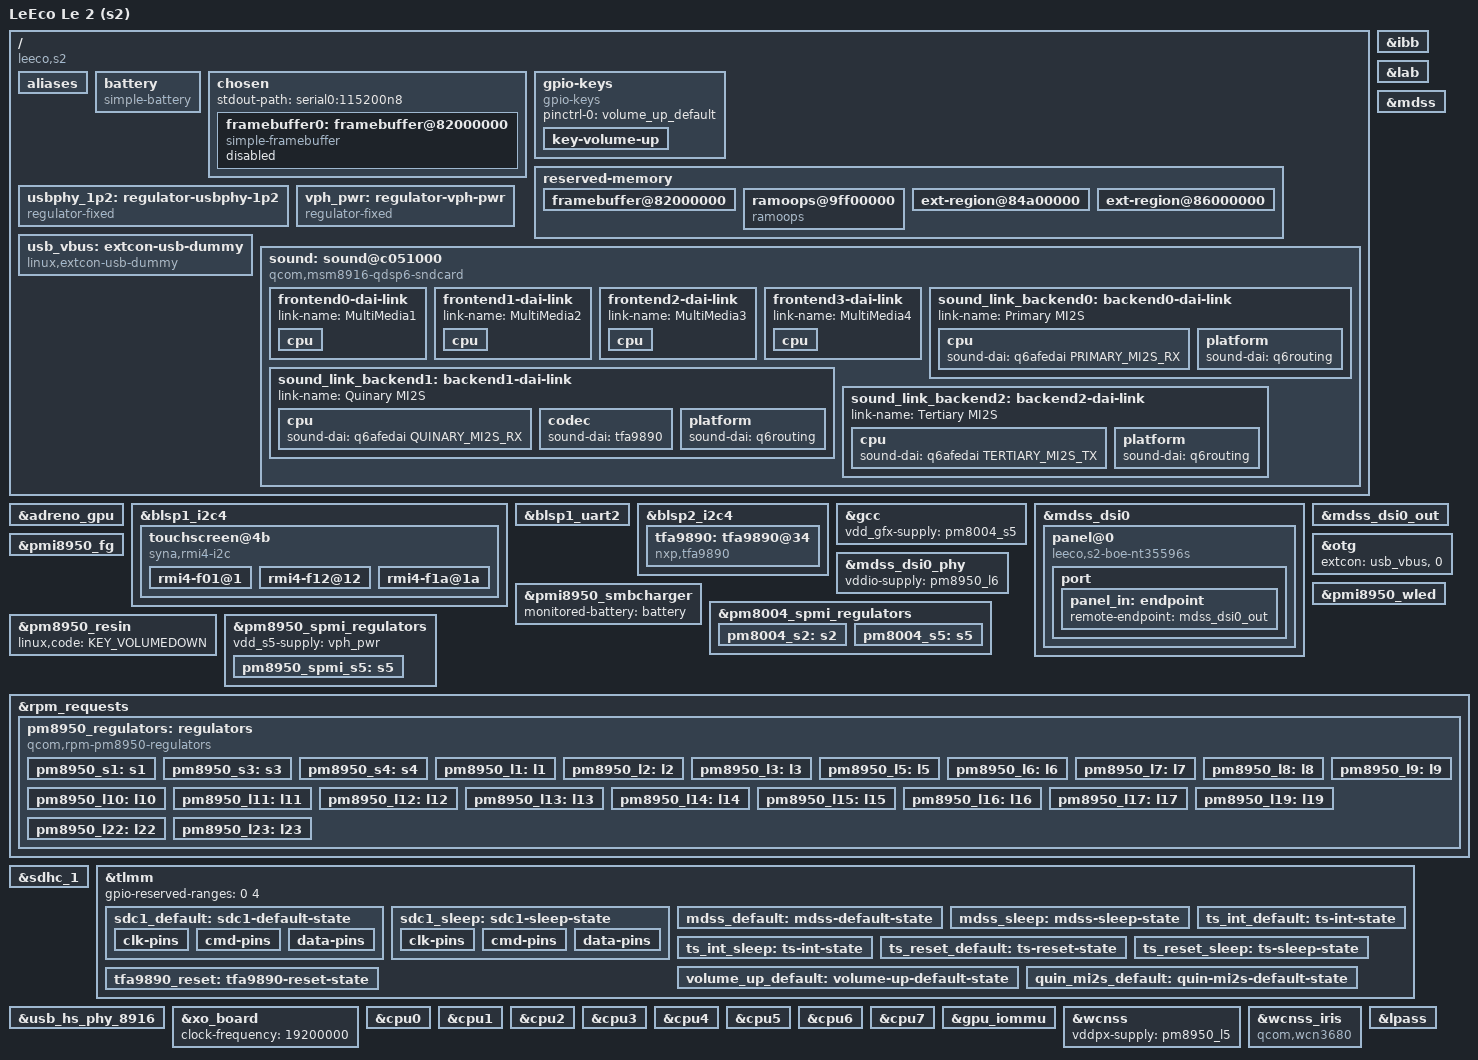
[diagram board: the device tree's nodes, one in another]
// SPDX-License-Identifier: BSD-3-Clause
/*
 * LeEco Le 2 (s2)
 */

/dts-v1/;

#include <dt-bindings/gpio/gpio.h>
#include <dt-bindings/input/input.h>
#include <dt-bindings/interrupt-controller/irq.h>

#include "msm8976.dtsi"
#include "pm8004.dtsi"
#include "pm8950.dtsi"
#include "pmi8950.dtsi"

/ {
	model = "LeEco Le 2 (s2)";
	compatible = "leeco,s2", "qcom,msm8976";
	chassis-type = "handset";

	aliases {
		mmc0 = &sdhc_1;
		serial0 = &blsp1_uart2;
	};

	battery: battery {
		compatible = "simple-battery";

		charge-full-design-microamp-hours = <3000000>;
		constant-charge-current-max-microamp = <1500000>;
		voltage-min-design-microvolt = <3400000>;
		voltage-max-design-microvolt = <4400000>;
	};

	chosen {
		stdout-path = "serial0:115200n8";

		#address-cells = <2>;
		#size-cells = <2>;
		ranges;

		framebuffer0: framebuffer@82000000 {
			compatible = "simple-framebuffer";
			reg = <0x0 0x82000000 0x0 (4352 * 1920)>;
			width = <1080>;
			height = <1920>;
			stride = <4352>;
			format = "a8r8g8b8";

			power-domains = <&gcc MDSS_GDSC>;

			clocks = <&gcc GCC_MDSS_AHB_CLK>,
				 <&gcc GCC_MDSS_AXI_CLK>,
				 <&gcc GCC_MDSS_VSYNC_CLK>,
				 <&gcc GCC_MDSS_MDP_CLK>,
				 <&gcc GCC_MDSS_BYTE0_CLK>,
				 <&gcc GCC_MDSS_PCLK0_CLK>,
				 <&gcc GCC_MDSS_ESC0_CLK>;

			status = "disabled";
		};
	};

	gpio-keys {
		compatible = "gpio-keys";

		pinctrl-0 = <&volume_up_default>;
		pinctrl-names = "default";

		key-volume-up {
			label = "Volume Up";
			gpios = <&tlmm 113 GPIO_ACTIVE_LOW>;
			linux,code = <KEY_VOLUMEUP>;
		};
	};

	reserved-memory {
		framebuffer@82000000 {
			reg = <0x0 0x82000000 0x0 0x2800000>;
			no-map;
		};

		ramoops@9ff00000 {
			compatible = "ramoops";
			reg = <0x0 0x9ff00000 0x0 0x100000>;
			record-size = <0x10000>;
			console-size = <0x60000>;
			pmsg-size = <0x20000>;
			no-map;
		};

		ext-region@84a00000 {
			reg = <0x0 0x84a00000 0x0 0x1100000>;
			no-map;
		};

		ext-region@86000000 {
			reg = <0x0 0x86000000 0x0 0x300000>;
			no-map;
		};
	};

	usbphy_1p2: regulator-usbphy-1p2 {
		compatible = "regulator-fixed";
		regulator-name = "usbphy-1p2";
		regulator-always-on;
		regulator-boot-on;
		regulator-min-microvolt = <1200000>;
		regulator-max-microvolt = <1200000>;
		vin-supply = <&vph_pwr>;
	};

	usb_vbus: extcon-usb-dummy {
		compatible = "linux,extcon-usb-dummy";
	};

	vph_pwr: regulator-vph-pwr {
		compatible = "regulator-fixed";
		regulator-name = "vph-pwr";
		regulator-always-on;
		regulator-boot-on;
	};

	sound: sound@c051000 {
		compatible = "qcom,msm8916-qdsp6-sndcard";
		model = "msm8976-leeco-s2";
		reg = <0x0 0x0c051000 0x0 0x4>, <0x0 0x0c051004 0x0 0x4>,
		      <0x0 0x0c052000 0x0 0x4>;
		reg-names = "mic-iomux", "spkr-iomux", "quin-iomux";

		pinctrl-0 = <&quin_mi2s_default>;
		pinctrl-names = "default";

		widgets = "Speaker", "Internal Speaker";
		audio-routing = "Internal Speaker", "OUT";

		status = "okay";

		frontend0-dai-link {
			link-name = "MultiMedia1";

			cpu {
				sound-dai = <&q6asmdai MSM_FRONTEND_DAI_MULTIMEDIA1>;
			};
		};

		frontend1-dai-link {
			link-name = "MultiMedia2";

			cpu {
				sound-dai = <&q6asmdai MSM_FRONTEND_DAI_MULTIMEDIA2>;
			};
		};

		frontend2-dai-link {
			link-name = "MultiMedia3";

			cpu {
				sound-dai = <&q6asmdai MSM_FRONTEND_DAI_MULTIMEDIA3>;
			};
		};

		frontend3-dai-link {
			link-name = "MultiMedia4";

			cpu {
				sound-dai = <&q6asmdai MSM_FRONTEND_DAI_MULTIMEDIA4>;
			};
		};

		sound_link_backend0: backend0-dai-link {
			link-name = "Primary MI2S";

			cpu {
				sound-dai = <&q6afedai PRIMARY_MI2S_RX>;
			};
			platform {
				sound-dai = <&q6routing>;
			};
		};

		sound_link_backend1: backend1-dai-link {
			link-name = "Quinary MI2S";

			cpu {
				sound-dai = <&q6afedai QUINARY_MI2S_RX>;
			};
			codec {
				sound-dai = <&tfa9890>;
			};
			platform {
				sound-dai = <&q6routing>;
			};
		};

		sound_link_backend2: backend2-dai-link {
			link-name = "Tertiary MI2S";

			cpu {
				sound-dai = <&q6afedai TERTIARY_MI2S_TX>;
			};
			platform {
				sound-dai = <&q6routing>;
			};
		};
	};
};

&adreno_gpu {
	status = "okay";
};

&blsp1_i2c4 {
	status = "okay";

	touchscreen@4b {
		compatible = "syna,rmi4-i2c";
		reg = <0x4b>;

		interrupts-extended = <&tlmm 65 IRQ_TYPE_EDGE_FALLING>;

		pinctrl-0 = <&ts_int_default>, <&ts_reset_default>;
		pinctrl-1 = <&ts_int_sleep>, <&ts_reset_sleep>;
		pinctrl-names = "default", "sleep";

		vdd-supply = <&pm8950_l17>;
		vio-supply = <&pm8950_l6>;

		reset-gpios = <&tlmm 64 GPIO_ACTIVE_LOW>;

		syna,reset-delay-ms = <200>;
		syna,startup-delay-ms = <200>;

		#address-cells = <1>;
		#size-cells = <0>;

		rmi4-f01@1 {
			reg = <0x1>;
			syna,nosleep-mode = <1>;
		};

		rmi4-f12@12 {
			reg = <0x12>;
			syna,sensor-type = <1>;
		};

		rmi4-f1a@1a {
			reg = <0x1a>;
			linux,keycodes = <KEY_MENU KEY_HOME KEY_BACK>;
		};
	};
};

&blsp1_uart2 {
	status = "okay";
};

&blsp2_i2c4 {
	status = "okay";

	tfa9890: tfa9890@34 {
		compatible = "nxp,tfa9890";
		reg = <0x34>;

		vddd-supply = <&pm8950_l5>;

		#sound-dai-cells = <0>;
	};
};

&gcc {
	vdd_gfx-supply = <&pm8004_s5>;
};

&ibb {
	regulator-min-microvolt = <4600000>;
	regulator-max-microvolt = <5900000>;
};

&lab {
	regulator-min-microvolt = <4600000>;
	regulator-max-microvolt = <5900000>;
};

&mdss {
	status = "okay";
};

&mdss_dsi0 {
	vdd-supply = <&pm8950_l17>;
	vdda-supply = <&pm8950_l1>;
	vddio-supply = <&pm8950_l6>;

	pinctrl-0 = <&mdss_default>;
	pinctrl-1 = <&mdss_sleep>;
	pinctrl-names = "default", "sleep";

	status = "okay";

	panel@0 {
		compatible = "leeco,s2-boe-nt35596s";
		reg = <0>;

		reset-gpios = <&tlmm 25 GPIO_ACTIVE_LOW>;

		vdd-supply = <&pm8950_l17>;
		vddio-supply = <&pm8950_l6>;
		lab-supply = <&lab>;
		ibb-supply = <&ibb>;

		backlight = <&pmi8950_wled>;

		port {
			panel_in: endpoint {
				remote-endpoint = <&mdss_dsi0_out>;
			};
		};
	};
};

&mdss_dsi0_out {
	data-lanes = <0 1 2 3>;
	remote-endpoint = <&panel_in>;
};

&mdss_dsi0_phy {
	vddio-supply = <&pm8950_l6>;
	status = "okay";
};

&pmi8950_fg {
	monitored-battery = <&battery>;
	power-supplies = <&pmi8950_smbcharger>;
	status = "okay";
};

&pmi8950_smbcharger {
	monitored-battery = <&battery>;
	status = "okay";
};

&otg {
	extcon = <&usb_vbus>, <0>;
	status = "okay";
};

&pmi8950_wled {
	status = "okay";

	qcom,switching-freq = <800>;
	qcom,ovp-millivolt = <29500>;
	qcom,current-boost-limit = <970>;
	qcom,current-limit-microamp = <20000>;
	qcom,enabled-strings = <0 1>;
	default-brightness = <2048>;
};

&pm8004_spmi_regulators {
	vdd_s2-supply = <&vph_pwr>;
	vdd_s5-supply = <&vph_pwr>;

	pm8004_s2: s2 {
		regulator-min-microvolt = <950000>;
		regulator-max-microvolt = <1165000>;
		regulator-name = "vdd_apc1";
		regulator-always-on;
		regulator-boot-on;
	};

	pm8004_s5: s5 {
		regulator-min-microvolt = <950000>;
		regulator-max-microvolt = <1165000>;
		regulator-enable-ramp-delay = <500>;
		regulator-name = "vdd_gfx";
		regulator-always-on;
	};
};

&pm8950_resin {
	linux,code = <KEY_VOLUMEDOWN>;
	status = "okay";
};

&pm8950_spmi_regulators {
	vdd_s5-supply = <&vph_pwr>;

	pm8950_spmi_s5: s5 {
		regulator-min-microvolt = <950000>;
		regulator-max-microvolt = <1165000>;
		regulator-name = "vdd_apc0";
		regulator-always-on;
		regulator-boot-on;
	};
};

&rpm_requests {
	pm8950_regulators: regulators {
		compatible = "qcom,rpm-pm8950-regulators";

		vdd_s1-supply = <&vph_pwr>;
		vdd_s2-supply = <&vph_pwr>;
		vdd_s3-supply = <&vph_pwr>;
		vdd_s4-supply = <&vph_pwr>;
		vdd_s6-supply = <&vph_pwr>;
		vdd_l1_l19-supply = <&pm8950_s3>;
		vdd_l2_l23-supply = <&pm8950_s3>;
		vdd_l3-supply = <&pm8950_s3>;
		vdd_l5_l6_l7_l16-supply = <&pm8950_s4>;
		vdd_l8_l11_l12_l17_l22-supply = <&vph_pwr>;

		pm8950_s1: s1 {
			regulator-min-microvolt = <1000000>;
			regulator-max-microvolt = <1162500>;
		};

		pm8950_s3: s3 {
			regulator-min-microvolt = <1325000>;
			regulator-max-microvolt = <1325000>;
		};

		pm8950_s4: s4 {
			regulator-min-microvolt = <2050000>;
			regulator-max-microvolt = <2050000>;
		};

		pm8950_l1: l1 {
			regulator-min-microvolt = <1200000>;
			regulator-max-microvolt = <1200000>;
		};

		pm8950_l2: l2 {
			regulator-min-microvolt = <1200000>;
			regulator-max-microvolt = <1200000>;
		};

		pm8950_l3: l3 {
			regulator-min-microvolt = <1000000>;
			regulator-max-microvolt = <1100000>;
		};

		pm8950_l5: l5 {
			regulator-min-microvolt = <1800000>;
			regulator-max-microvolt = <1800000>;
		};

		pm8950_l6: l6 {
			regulator-min-microvolt = <1800000>;
			regulator-max-microvolt = <1800000>;
		};

		pm8950_l7: l7 {
			regulator-min-microvolt = <1800000>;
			regulator-max-microvolt = <1800000>;
		};

		pm8950_l8: l8 {
			regulator-min-microvolt = <2900000>;
			regulator-max-microvolt = <2900000>;
		};

		pm8950_l9: l9 {
			regulator-min-microvolt = <3000000>;
			regulator-max-microvolt = <3300000>;
		};

		pm8950_l10: l10 {
			regulator-min-microvolt = <2800000>;
			regulator-max-microvolt = <2800000>;
		};

		pm8950_l11: l11 {
			regulator-min-microvolt = <2950000>;
			regulator-max-microvolt = <2950000>;
		};

		pm8950_l12: l12 {
			regulator-min-microvolt = <1800000>;
			regulator-max-microvolt = <2950000>;
		};

		pm8950_l13: l13 {
			regulator-min-microvolt = <3075000>;
			regulator-max-microvolt = <3075000>;
		};

		pm8950_l14: l14 {
			regulator-min-microvolt = <1800000>;
			regulator-max-microvolt = <3300000>;
		};

		pm8950_l15: l15 {
			regulator-min-microvolt = <1800000>;
			regulator-max-microvolt = <3300000>;
		};

		pm8950_l16: l16 {
			regulator-min-microvolt = <1800000>;
			regulator-max-microvolt = <1800000>;
		};

		pm8950_l17: l17 {
			regulator-min-microvolt = <2850000>;
			regulator-max-microvolt = <2850000>;
		};

		pm8950_l19: l19 {
			regulator-min-microvolt = <1200000>;
			regulator-max-microvolt = <1350000>;
		};

		pm8950_l22: l22 {
			regulator-min-microvolt = <2800000>;
			regulator-max-microvolt = <2800000>;
		};

		pm8950_l23: l23 {
			regulator-min-microvolt = <1200000>;
			regulator-max-microvolt = <1200000>;
		};
	};
};

&sdhc_1 {
	bus-width = <8>;
	non-removable;
	max-frequency = <100000000>;
	pinctrl-names = "default", "sleep";
	pinctrl-0 = <&sdc1_default>;
	pinctrl-1 = <&sdc1_sleep>;
	vmmc-supply = <&pm8950_l8>;
	vqmmc-supply = <&pm8950_l5>;
	status = "okay";
};

&tlmm {
	gpio-reserved-ranges = <0 4>;

	sdc1_default: sdc1-default-state {
		clk-pins {
			pins = "sdc1_clk";
			bias-disable;
			drive-strength = <16>;
		};

		cmd-pins {
			pins = "sdc1_cmd";
			bias-pull-up;
			drive-strength = <10>;
		};

		data-pins {
			pins = "sdc1_data";
			bias-pull-up;
			drive-strength = <10>;
		};
	};

	sdc1_sleep: sdc1-sleep-state {
		clk-pins {
			pins = "sdc1_clk";
			bias-disable;
			drive-strength = <2>;
		};

		cmd-pins {
			pins = "sdc1_cmd";
			bias-pull-up;
			drive-strength = <2>;
		};

		data-pins {
			pins = "sdc1_data";
			bias-pull-up;
			drive-strength = <2>;
		};
	};

	mdss_default: mdss-default-state {
		pins = "gpio25";
		function = "gpio";
		drive-strength = <8>;
		bias-disable;
	};

	mdss_sleep: mdss-sleep-state {
		pins = "gpio25";
		function = "gpio";
		drive-strength = <2>;
		bias-pull-down;
	};

	ts_int_default: ts-int-state {
		pins = "gpio65";
		function = "gpio";
		drive-strength = <2>;
		bias-pull-down;
	};

	ts_int_sleep: ts-int-state {
		pins = "gpio65";
		function = "gpio";
		drive-strength = <2>;
		bias-pull-up;
	};

	ts_reset_default: ts-reset-state {
		pins = "gpio64";
		function = "gpio";
		drive-strength = <8>;
		bias-pull-up;
	};

	ts_reset_sleep: ts-sleep-state {
		pins = "gpio64";
		function = "gpio";
		drive-strength = <2>;
		bias-pull-down;
	};

	volume_up_default: volume-up-default-state {
		pins = "gpio113";
		function = "gpio";
		drive-strength = <2>;
		bias-pull-up;
	};

	quin_mi2s_default: quin-mi2s-default-state {
		pins = "gpio123", "gpio124", "gpio125", "gpio127";
		function = "pri_mi2s";
		drive-strength = <8>;
		bias-disable;
	};

	tfa9890_reset: tfa9890-reset-state {
		gpio-hog;
		gpios = <129 GPIO_ACTIVE_HIGH>;
		output-low;
		line-name = "tfa9890-reset";
	};
};

&usb_hs_phy_8916 {
	v1p8-supply = <&pm8950_l7>;
	v3p3-supply = <&pm8950_l13>;
	extcon = <&usb_vbus>;
	status = "okay";
};

&xo_board {
	clock-frequency = <19200000>;
};

&cpu0 {
	/delete-property/ cpu-idle-states;
};

&cpu1 {
	/delete-property/ cpu-idle-states;
};

&cpu2 {
	/delete-property/ cpu-idle-states;
};

&cpu3 {
	/delete-property/ cpu-idle-states;
};

&cpu4 {
	/delete-property/ cpu-idle-states;
};

&cpu5 {
	/delete-property/ cpu-idle-states;
};

&cpu6 {
	/delete-property/ cpu-idle-states;
};

&cpu7 {
	/delete-property/ cpu-idle-states;
};

&gpu_iommu {
	status = "okay";
};

&wcnss {
	vddpx-supply = <&pm8950_l5>;
	status = "okay";
};

&wcnss_iris {
	compatible = "qcom,wcn3680";
	vddxo-supply = <&pm8950_l7>;
	vddrfa-supply = <&pm8950_l19>;
	vddpa-supply = <&pm8950_l9>;
	vdddig-supply = <&pm8950_l5>;
	status = "okay";
};

&lpass {
	status = "okay";
};
